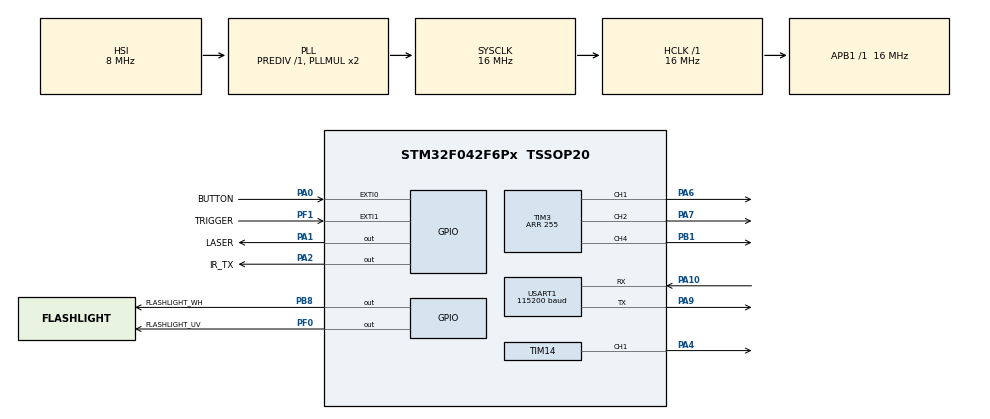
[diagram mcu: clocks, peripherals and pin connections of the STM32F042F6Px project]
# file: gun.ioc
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Mcu.Family=STM32F0
Mcu.Name=STM32F042F6Px
Mcu.Package=TSSOP20
NVIC.EXTI0_1_IRQn=true\:2\:0\:true\:false\:true\:true
NVIC.USART1_IRQn=true\:1\:0\:true\:false\:true\:true
PA0.GPIO_Label=BUTTON
PA0.GPIO_ModeDefaultEXTI=GPIO_MODE_IT_RISING_FALLING
PA0.GPIO_PuPd=GPIO_PULLUP
PA0.Signal=GPXTI0
PA1.GPIO_Label=LASER
PA1.Signal=GPIO_Output
PA10.Mode=Asynchronous
PA10.Signal=USART1_RX
PA13.Mode=Serial_Wire
PA13.Signal=SYS_SWDIO
PA14.Mode=Serial_Wire
PA14.Signal=SYS_SWCLK
PA2.GPIO_Label=IR_TX
PA2.Signal=GPIO_Output
PA4.Signal=S_TIM14_CH1
PA6.Signal=S_TIM3_CH1
PA7.Signal=S_TIM3_CH2
PA9.Mode=Asynchronous
PA9.Signal=USART1_TX
PB1.Signal=S_TIM3_CH4
PB8.GPIO_Label=FLASHLIGHT_WH
PB8.Signal=GPIO_Output
PF0-OSC_IN.GPIO_Label=FLASHLIGHT_UV
PF0-OSC_IN.Signal=GPIO_Output
PF1-OSC_OUT.GPIO_Label=TRIGGER
PF1-OSC_OUT.GPIO_ModeDefaultEXTI=GPIO_MODE_IT_RISING_FALLING
PF1-OSC_OUT.GPIO_PuPd=GPIO_PULLUP
PF1-OSC_OUT.Signal=GPXTI1
ProjectManager.HeapSize=0x200
ProjectManager.StackSize=0x400
ProjectManager.TargetToolchain=Makefile
RCC.AHBFreq_Value=16000000
RCC.APB1Freq_Value=16000000
RCC.APB1TimFreq_Value=16000000
RCC.HCLKFreq_Value=16000000
RCC.SYSCLKFreq_VALUE=16000000
RCC.SYSCLKSource=RCC_SYSCLKSOURCE_PLLCLK
SH.S_TIM14_CH1.0=TIM14_CH1,Output Compare1 CH1
SH.S_TIM3_CH1.0=TIM3_CH1,PWM Generation1 CH1
SH.S_TIM3_CH2.0=TIM3_CH2,PWM Generation2 CH2
SH.S_TIM3_CH4.0=TIM3_CH4,PWM Generation4 CH4
TIM14.AutoReloadPreload=TIM_AUTORELOAD_PRELOAD_DISABLE
TIM14.Channel=TIM_CHANNEL_1
TIM14.OCMode_1=TIM_OCMODE_TOGGLE
TIM14.Period=209
TIM14.Prescaler=0
TIM14.Pulse=209
TIM16.Period=0xFFFF
TIM16.Prescaler=15
TIM3.AutoReloadPreload=TIM_AUTORELOAD_PRELOAD_ENABLE
TIM3.Channel-PWM\ Generation1\ CH1=TIM_CHANNEL_1
TIM3.Channel-PWM\ Generation2\ CH2=TIM_CHANNEL_2
TIM3.Channel-PWM\ Generation4\ CH4=TIM_CHANNEL_4
TIM3.Period=255
USART1.BaudRate=115200
USART1.VirtualMode=VM_ASYNC
VP_TIM14_VS_ClockSourceINT.Mode=Enable_Timer
VP_TIM16_VS_ClockSourceINT.Mode=Enable_Timer
board=custom

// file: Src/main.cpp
/**
 ******************************************************************************
 * @file           : main.c
 * @brief          : Main program body
 ******************************************************************************
 ** This notice applies to any and all portions of this file
 * that are not between comment pairs USER CODE BEGIN and
 * USER CODE END. Other portions of this file, whether
 * inserted by the user or by software development tools
 * are owned by their respective copyright owners.
 *
 * COPYRIGHT(c) 2018 STMicroelectronics
 *
 * Redistribution and use in source and binary forms, with or without modification,
 * are permitted provided that the following conditions are met:
 *   1. Redistributions of source code must retain the above copyright notice,
 *      this list of conditions and the following disclaimer.
 *   2. Redistributions in binary form must reproduce the above copyright notice,
 *      this list of conditions and the following disclaimer in the documentation
 *      and/or other materials provided with the distribution.
 *   3. Neither the name of STMicroelectronics nor the names of its contributors
 *      may be used to endorse or promote products derived from this software
 *      without specific prior written permission.
 *
 * THIS SOFTWARE IS PROVIDED BY THE COPYRIGHT HOLDERS AND CONTRIBUTORS "AS IS"
 * AND ANY EXPRESS OR IMPLIED WARRANTIES, INCLUDING, BUT NOT LIMITED TO, THE
 * IMPLIED WARRANTIES OF MERCHANTABILITY AND FITNESS FOR A PARTICULAR PURPOSE ARE
 * DISCLAIMED. IN NO EVENT SHALL THE COPYRIGHT HOLDER OR CONTRIBUTORS BE LIABLE
 * FOR ANY DIRECT, INDIRECT, INCIDENTAL, SPECIAL, EXEMPLARY, OR CONSEQUENTIAL
 * DAMAGES (INCLUDING, BUT NOT LIMITED TO, PROCUREMENT OF SUBSTITUTE GOODS OR
 * SERVICES; LOSS OF USE, DATA, OR PROFITS; OR BUSINESS INTERRUPTION) HOWEVER
 * CAUSED AND ON ANY THEORY OF LIABILITY, WHETHER IN CONTRACT, STRICT LIABILITY,
 * OR TORT (INCLUDING NEGLIGENCE OR OTHERWISE) ARISING IN ANY WAY OUT OF THE USE
 * OF THIS SOFTWARE, EVEN IF ADVISED OF THE POSSIBILITY OF SUCH DAMAGE.
 *
 ******************************************************************************
 */
#include "main.h"
#include "stm32f0xx_hal.h"

/* USER CODE BEGIN Includes */
#include "global.hpp"
/* USER CODE END Includes */

TIM_HandleTypeDef htim3;
TIM_HandleTypeDef htim14;
TIM_HandleTypeDef htim16;

UART_HandleTypeDef huart1;

/* USER CODE BEGIN PV */
/* Private variables ---------------------------------------------------------*/

/* USER CODE END PV */

void SystemClock_Config(void);
static void MX_GPIO_Init(void);
static void MX_USART1_UART_Init(void);
static void MX_TIM3_Init(void);
static void MX_TIM14_Init(void);
static void MX_TIM16_Init(void);
#ifdef __cplusplus
extern "C" {
#endif
void HAL_TIM_MspPostInit(TIM_HandleTypeDef *htim);
#ifdef __cplusplus
}
#endif

/* USER CODE BEGIN PFP */
/* Private function prototypes -----------------------------------------------*/

/* USER CODE END PFP */

int main(void)
{

    /* MCU Configuration----------------------------------------------------------*/

    /* Reset of all peripherals, Initializes the Flash interface and the Systick. */
    HAL_Init();

    /* Configure the system clock */
    SystemClock_Config();

    /* Initialize all configured peripherals */
    MX_GPIO_Init();
    MX_USART1_UART_Init();
    MX_TIM3_Init();
    MX_TIM14_Init();
    MX_TIM16_Init();
    /* USER CODE BEGIN 2 */
    global->init();
    global->laser         = new Out(LASER_GPIO_Port, LASER_Pin, 1);
    global->flashlight_wh = new Out(FLASHLIGHT_WH_GPIO_Port, FLASHLIGHT_WH_Pin, 1);
    global->flashlight_uv = new Out(FLASHLIGHT_UV_GPIO_Port, FLASHLIGHT_UV_Pin, 1);
    global->trigger       = new In(TRIGGER_GPIO_Port, TRIGGER_Pin);
    global->button        = new In(BUTTON_GPIO_Port, BUTTON_Pin);
    global->uart         = new UART(&huart1);
    global->color_driver = new ColorDriver(&htim3, TIM_CHANNEL_4, TIM_CHANNEL_2, TIM_CHANNEL_1);
    global->ir = new IR(IR_TX_GPIO_Port, IR_TX_Pin, &htim16, &htim14, TIM_CHANNEL_1);

    /* USER CODE END 2 */

    /* Infinite loop */
    while (1)
    {

    }
} // main

void SystemClock_Config(void)
{
    RCC_OscInitTypeDef RCC_OscInitStruct;
    RCC_ClkInitTypeDef RCC_ClkInitStruct;
    RCC_PeriphCLKInitTypeDef PeriphClkInit;

    /**Initializes the CPU, AHB and APB busses clocks
     */
    RCC_OscInitStruct.OscillatorType      = RCC_OSCILLATORTYPE_HSI;
    RCC_OscInitStruct.HSIState            = RCC_HSI_ON;
    RCC_OscInitStruct.HSICalibrationValue = 16;
    RCC_OscInitStruct.PLL.PLLState        = RCC_PLL_ON;
    RCC_OscInitStruct.PLL.PLLSource       = RCC_PLLSOURCE_HSI;
    RCC_OscInitStruct.PLL.PLLMUL          = RCC_PLL_MUL2;
    RCC_OscInitStruct.PLL.PREDIV          = RCC_PREDIV_DIV1;
    if (HAL_RCC_OscConfig(&RCC_OscInitStruct) != HAL_OK)
    {
        _Error_Handler(__FILE__, __LINE__);
    }

    /**Initializes the CPU, AHB and APB busses clocks
     */
    RCC_ClkInitStruct.ClockType = RCC_CLOCKTYPE_HCLK | RCC_CLOCKTYPE_SYSCLK
      | RCC_CLOCKTYPE_PCLK1;
    RCC_ClkInitStruct.SYSCLKSource   = RCC_SYSCLKSOURCE_PLLCLK;
    RCC_ClkInitStruct.AHBCLKDivider  = RCC_SYSCLK_DIV1;
    RCC_ClkInitStruct.APB1CLKDivider = RCC_HCLK_DIV1;

    if (HAL_RCC_ClockConfig(&RCC_ClkInitStruct, FLASH_LATENCY_0) != HAL_OK)
    {
        _Error_Handler(__FILE__, __LINE__);
    }

    PeriphClkInit.PeriphClockSelection = RCC_PERIPHCLK_USART1;
    PeriphClkInit.Usart1ClockSelection = RCC_USART1CLKSOURCE_PCLK1;
    if (HAL_RCCEx_PeriphCLKConfig(&PeriphClkInit) != HAL_OK)
    {
        _Error_Handler(__FILE__, __LINE__);
    }

    /**Configure the Systick interrupt time
     */
    HAL_SYSTICK_Config(HAL_RCC_GetHCLKFreq() / 1000);

    /**Configure the Systick
     */
    HAL_SYSTICK_CLKSourceConfig(SYSTICK_CLKSOURCE_HCLK);

    /* SysTick_IRQn interrupt configuration */
    HAL_NVIC_SetPriority(SysTick_IRQn, 0, 0);
} // SystemClock_Config

/* TIM3 init function */
static void MX_TIM3_Init(void)
{
    TIM_MasterConfigTypeDef sMasterConfig;
    TIM_OC_InitTypeDef sConfigOC;

    htim3.Instance               = TIM3;
    htim3.Init.Prescaler         = 0;
    htim3.Init.CounterMode       = TIM_COUNTERMODE_UP;
    htim3.Init.Period            = 255;
    htim3.Init.ClockDivision     = TIM_CLOCKDIVISION_DIV1;
    htim3.Init.AutoReloadPreload = TIM_AUTORELOAD_PRELOAD_ENABLE;
    if (HAL_TIM_PWM_Init(&htim3) != HAL_OK)
    {
        _Error_Handler(__FILE__, __LINE__);
    }

    sMasterConfig.MasterOutputTrigger = TIM_TRGO_RESET;
    sMasterConfig.MasterSlaveMode     = TIM_MASTERSLAVEMODE_DISABLE;
    if (HAL_TIMEx_MasterConfigSynchronization(&htim3, &sMasterConfig) != HAL_OK)
    {
        _Error_Handler(__FILE__, __LINE__);
    }

    sConfigOC.OCMode     = TIM_OCMODE_PWM1;
    sConfigOC.Pulse      = 0;
    sConfigOC.OCPolarity = TIM_OCPOLARITY_HIGH;
    sConfigOC.OCFastMode = TIM_OCFAST_DISABLE;
    if (HAL_TIM_PWM_ConfigChannel(&htim3, &sConfigOC, TIM_CHANNEL_1) != HAL_OK)
    {
        _Error_Handler(__FILE__, __LINE__);
    }

    if (HAL_TIM_PWM_ConfigChannel(&htim3, &sConfigOC, TIM_CHANNEL_2) != HAL_OK)
    {
        _Error_Handler(__FILE__, __LINE__);
    }

    if (HAL_TIM_PWM_ConfigChannel(&htim3, &sConfigOC, TIM_CHANNEL_4) != HAL_OK)
    {
        _Error_Handler(__FILE__, __LINE__);
    }

    HAL_TIM_MspPostInit(&htim3);
} // MX_TIM3_Init

/* TIM14 init function */
static void MX_TIM14_Init(void)
{
    TIM_OC_InitTypeDef sConfigOC;

    htim14.Instance               = TIM14;
    htim14.Init.Prescaler         = 0;
    htim14.Init.CounterMode       = TIM_COUNTERMODE_UP;
    htim14.Init.Period            = 209;
    htim14.Init.ClockDivision     = TIM_CLOCKDIVISION_DIV1;
    htim14.Init.AutoReloadPreload = TIM_AUTORELOAD_PRELOAD_DISABLE;
    if (HAL_TIM_Base_Init(&htim14) != HAL_OK)
    {
        _Error_Handler(__FILE__, __LINE__);
    }

    if (HAL_TIM_OC_Init(&htim14) != HAL_OK)
    {
        _Error_Handler(__FILE__, __LINE__);
    }

    sConfigOC.OCMode     = TIM_OCMODE_TOGGLE;
    sConfigOC.Pulse      = 209;
    sConfigOC.OCPolarity = TIM_OCPOLARITY_HIGH;
    sConfigOC.OCFastMode = TIM_OCFAST_DISABLE;
    if (HAL_TIM_OC_ConfigChannel(&htim14, &sConfigOC, TIM_CHANNEL_1) != HAL_OK)
    {
        _Error_Handler(__FILE__, __LINE__);
    }

    HAL_TIM_MspPostInit(&htim14);
}

/* TIM16 init function */
static void MX_TIM16_Init(void)
{
    htim16.Instance               = TIM16;
    htim16.Init.Prescaler         = 15;
    htim16.Init.CounterMode       = TIM_COUNTERMODE_UP;
    htim16.Init.Period            = 0xFFFF;
    htim16.Init.ClockDivision     = TIM_CLOCKDIVISION_DIV1;
    htim16.Init.RepetitionCounter = 0;
    htim16.Init.AutoReloadPreload = TIM_AUTORELOAD_PRELOAD_DISABLE;
    if (HAL_TIM_Base_Init(&htim16) != HAL_OK)
    {
        _Error_Handler(__FILE__, __LINE__);
    }
}

/* USART1 init function */
static void MX_USART1_UART_Init(void)
{
    huart1.Instance                    = USART1;
    huart1.Init.BaudRate               = 115200;
    huart1.Init.WordLength             = UART_WORDLENGTH_8B;
    huart1.Init.StopBits               = UART_STOPBITS_1;
    huart1.Init.Parity                 = UART_PARITY_NONE;
    huart1.Init.Mode                   = UART_MODE_TX_RX;
    huart1.Init.HwFlowCtl              = UART_HWCONTROL_NONE;
    huart1.Init.OverSampling           = UART_OVERSAMPLING_16;
    huart1.Init.OneBitSampling         = UART_ONE_BIT_SAMPLE_DISABLE;
    huart1.AdvancedInit.AdvFeatureInit = UART_ADVFEATURE_NO_INIT;
    if (HAL_UART_Init(&huart1) != HAL_OK)
    {
        _Error_Handler(__FILE__, __LINE__);
    }
}

/** Configure pins as
 * Analog
 * Input
 * Output
 * EVENT_OUT
 * EXTI
 */
static void MX_GPIO_Init(void)
{
    GPIO_InitTypeDef GPIO_InitStruct;

    /* GPIO Ports Clock Enable */
    __HAL_RCC_GPIOB_CLK_ENABLE();
    __HAL_RCC_GPIOF_CLK_ENABLE();
    __HAL_RCC_GPIOA_CLK_ENABLE();

    /*Configure GPIO pin Output Level */
    HAL_GPIO_WritePin(FLASHLIGHT_WH_GPIO_Port, FLASHLIGHT_WH_Pin, GPIO_PIN_RESET);

    /*Configure GPIO pin Output Level */
    HAL_GPIO_WritePin(FLASHLIGHT_UV_GPIO_Port, FLASHLIGHT_UV_Pin, GPIO_PIN_RESET);

    /*Configure GPIO pin Output Level */
    HAL_GPIO_WritePin(GPIOA, LASER_Pin | IR_TX_Pin, GPIO_PIN_RESET);

    /*Configure GPIO pin : FLASHLIGHT_WH_Pin */
    GPIO_InitStruct.Pin   = FLASHLIGHT_WH_Pin;
    GPIO_InitStruct.Mode  = GPIO_MODE_OUTPUT_PP;
    GPIO_InitStruct.Pull  = GPIO_NOPULL;
    GPIO_InitStruct.Speed = GPIO_SPEED_FREQ_LOW;
    HAL_GPIO_Init(FLASHLIGHT_WH_GPIO_Port, &GPIO_InitStruct);

    /*Configure GPIO pin : FLASHLIGHT_UV_Pin */
    GPIO_InitStruct.Pin   = FLASHLIGHT_UV_Pin;
    GPIO_InitStruct.Mode  = GPIO_MODE_OUTPUT_PP;
    GPIO_InitStruct.Pull  = GPIO_NOPULL;
    GPIO_InitStruct.Speed = GPIO_SPEED_FREQ_LOW;
    HAL_GPIO_Init(FLASHLIGHT_UV_GPIO_Port, &GPIO_InitStruct);

    /*Configure GPIO pin : TRIGGER_Pin */
    GPIO_InitStruct.Pin  = TRIGGER_Pin;
    GPIO_InitStruct.Mode = GPIO_MODE_IT_RISING_FALLING;
    GPIO_InitStruct.Pull = GPIO_PULLUP;
    HAL_GPIO_Init(TRIGGER_GPIO_Port, &GPIO_InitStruct);

    /*Configure GPIO pin : BUTTON_Pin */
    GPIO_InitStruct.Pin  = BUTTON_Pin;
    GPIO_InitStruct.Mode = GPIO_MODE_IT_RISING_FALLING;
    GPIO_InitStruct.Pull = GPIO_PULLUP;
    HAL_GPIO_Init(BUTTON_GPIO_Port, &GPIO_InitStruct);

    /*Configure GPIO pins : LASER_Pin IR_TX_Pin */
    GPIO_InitStruct.Pin   = LASER_Pin | IR_TX_Pin;
    GPIO_InitStruct.Mode  = GPIO_MODE_OUTPUT_PP;
    GPIO_InitStruct.Pull  = GPIO_NOPULL;
    GPIO_InitStruct.Speed = GPIO_SPEED_FREQ_LOW;
    HAL_GPIO_Init(GPIOA, &GPIO_InitStruct);

    /* EXTI interrupt init*/
    HAL_NVIC_SetPriority(EXTI0_1_IRQn, 2, 0);
    HAL_NVIC_EnableIRQ(EXTI0_1_IRQn);
} // MX_GPIO_Init

void _Error_Handler(char *file, int line)
{
    /* USER CODE BEGIN Error_Handler_Debug */
    /* User can add his own implementation to report the HAL error return state */
    while (1)
    { }
    /* USER CODE END Error_Handler_Debug */
}

#ifdef  USE_FULL_ASSERT

/**
 * @brief  Reports the name of the source file and the source line number
 *         where the assert_param error has occurred.
 * @param  file: pointer to the source file name
 * @param  line: assert_param error line source number
 * @retval None
 */
void assert_failed(uint8_t *file, uint32_t line)
{
    /* USER CODE BEGIN 6 */

    /* User can add his own implementation to report the file name and line number,
     * tex: printf("Wrong parameters value: file %s on line %d\r\n", file, line) */
    /* USER CODE END 6 */
}

#endif /* USE_FULL_ASSERT */

/************************ (C) COPYRIGHT STMicroelectronics *****END OF FILE****/
